VERSION ""

NS_ :

BS_:

BU_:

BO_ 2183149062 HeadLight_3606: 8 Vector__XXX
 SG_ HeadLightOn : 15|8@0+ (1,0) [0|0] "" Vector__XXX
 SG_ BusAwake : 7|8@0+ (1,0) [0|0] "" Vector__XXX

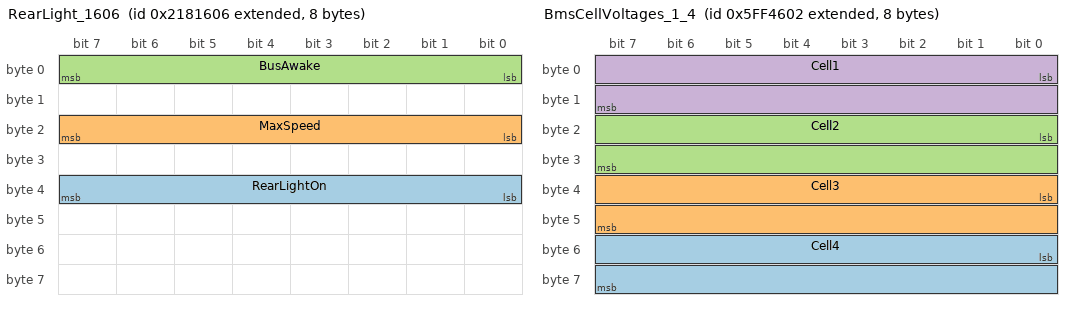
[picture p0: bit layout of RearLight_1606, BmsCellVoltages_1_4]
BO_ 2182616582 RearLight_1606: 8 Vector__XXX
 SG_ RearLightOn : 39|8@0+ (1,0) [0|0] "" Vector__XXX
 SG_ MaxSpeed : 23|8@0+ (1,0) [0|0] "km/h" Vector__XXX
 SG_ BusAwake : 7|8@0+ (1,0) [0|0] "" Vector__XXX

BO_ 2478269440 Lock_6400: 1 Vector__XXX
 SG_ Unlocked : 7|8@0+ (1,0) [0|0] "" Vector__XXX

BO_ 2214532608 SpeedLimit_1600: 8 Vector__XXX
 SG_ MaxSpeed : 63|8@0+ (1,0) [0|0] "km/h" Vector__XXX

BO_ 2248099330 BmsCellVoltages_1_4: 8 Vector__XXX
 SG_ Cell4 : 48|16@1+ (1,0) [0|0] "mV" Vector__XXX
 SG_ Cell3 : 32|16@1+ (1,0) [0|0] "mV" Vector__XXX
 SG_ Cell2 : 16|16@1+ (1,0) [0|0] "mV" Vector__XXX
 SG_ Cell1 : 0|16@1+ (1,0) [0|0] "mV" Vector__XXX

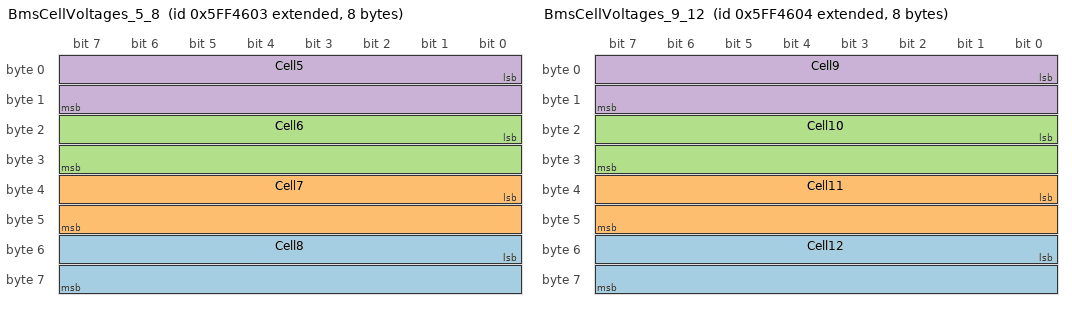
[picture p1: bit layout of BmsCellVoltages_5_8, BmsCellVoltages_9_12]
BO_ 2248099331 BmsCellVoltages_5_8: 8 Vector__XXX
 SG_ Cell8 : 48|16@1+ (1,0) [0|0] "mV" Vector__XXX
 SG_ Cell7 : 32|16@1+ (1,0) [0|0] "mV" Vector__XXX
 SG_ Cell6 : 16|16@1+ (1,0) [0|0] "mV" Vector__XXX
 SG_ Cell5 : 0|16@1+ (1,0) [0|0] "mV" Vector__XXX

BO_ 2248099332 BmsCellVoltages_9_12: 8 Vector__XXX
 SG_ Cell12 : 48|16@1+ (1,0) [0|0] "mV" Vector__XXX
 SG_ Cell11 : 32|16@1+ (1,0) [0|0] "mV" Vector__XXX
 SG_ Cell10 : 16|16@1+ (1,0) [0|0] "mV" Vector__XXX
 SG_ Cell9 : 0|16@1+ (1,0) [0|0] "mV" Vector__XXX

BO_ 2248099333 BmsCellVoltage_13: 8 Vector__XXX
 SG_ Cell13 : 0|16@1+ (1,0) [0|0] "mV" Vector__XXX

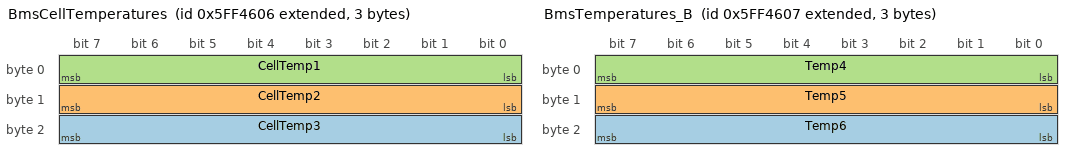
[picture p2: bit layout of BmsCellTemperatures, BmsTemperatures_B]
BO_ 2248099334 BmsCellTemperatures: 3 Vector__XXX
 SG_ CellTemp3 : 23|8@0+ (1,0) [0|0] "degC" Vector__XXX
 SG_ CellTemp2 : 15|8@0+ (1,0) [0|0] "degC" Vector__XXX
 SG_ CellTemp1 : 7|8@0+ (1,0) [0|0] "degC" Vector__XXX

BO_ 2248099335 BmsTemperatures_B: 3 Vector__XXX
 SG_ Temp6 : 23|8@0+ (1,0) [0|0] "degC" Vector__XXX
 SG_ Temp5 : 15|8@0+ (1,0) [0|0] "degC" Vector__XXX
 SG_ Temp4 : 7|8@0+ (1,0) [0|0] "degC" Vector__XXX

BO_ 2248099344 BmsPackVoltageCurrent: 8 Vector__XXX
 SG_ PackCurrent : 39|32@0- (1,0) [0|0] "mA" Vector__XXX
 SG_ PackVoltage : 7|32@0+ (1,0) [0|0] "mV" Vector__XXX

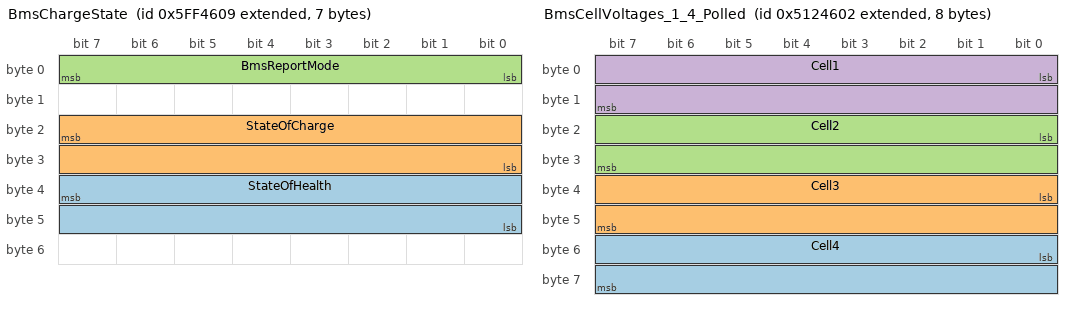
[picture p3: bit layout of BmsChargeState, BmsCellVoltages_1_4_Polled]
BO_ 2248099337 BmsChargeState: 7 Vector__XXX
 SG_ StateOfHealth : 39|16@0+ (0.1,0) [0|0] "%" Vector__XXX
 SG_ StateOfCharge : 23|16@0+ (0.1,0) [0|0] "%" Vector__XXX
 SG_ BmsReportMode : 7|8@0+ (1,0) [0|0] "" Vector__XXX

BO_ 2232567305 BmsChargeStatePolled: 7 Vector__XXX
 SG_ StateOfHealth : 39|16@0+ (0.1,0) [0|0] "%" Vector__XXX
 SG_ StateOfCharge : 23|16@0+ (0.1,0) [0|0] "%" Vector__XXX

BO_ 2232567297 BmsStatusFlagsPolled: 6 Vector__XXX

BO_ 2232567298 BmsCellVoltages_1_4_Polled: 8 Vector__XXX
 SG_ Cell4 : 48|16@1+ (1,0) [0|0] "mV" Vector__XXX
 SG_ Cell3 : 32|16@1+ (1,0) [0|0] "mV" Vector__XXX
 SG_ Cell2 : 16|16@1+ (1,0) [0|0] "mV" Vector__XXX
 SG_ Cell1 : 0|16@1+ (1,0) [0|0] "mV" Vector__XXX

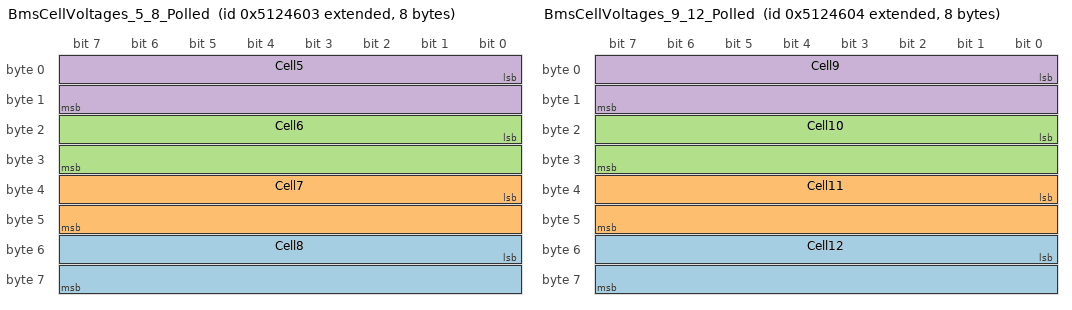
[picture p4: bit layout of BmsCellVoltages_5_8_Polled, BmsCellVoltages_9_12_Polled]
BO_ 2232567299 BmsCellVoltages_5_8_Polled: 8 Vector__XXX
 SG_ Cell8 : 48|16@1+ (1,0) [0|0] "mV" Vector__XXX
 SG_ Cell7 : 32|16@1+ (1,0) [0|0] "mV" Vector__XXX
 SG_ Cell6 : 16|16@1+ (1,0) [0|0] "mV" Vector__XXX
 SG_ Cell5 : 0|16@1+ (1,0) [0|0] "mV" Vector__XXX

BO_ 2232567300 BmsCellVoltages_9_12_Polled: 8 Vector__XXX
 SG_ Cell12 : 48|16@1+ (1,0) [0|0] "mV" Vector__XXX
 SG_ Cell11 : 32|16@1+ (1,0) [0|0] "mV" Vector__XXX
 SG_ Cell10 : 16|16@1+ (1,0) [0|0] "mV" Vector__XXX
 SG_ Cell9 : 0|16@1+ (1,0) [0|0] "mV" Vector__XXX

BO_ 2232567301 BmsCellVoltage_13_Polled: 8 Vector__XXX
 SG_ Cell13 : 0|16@1+ (1,0) [0|0] "mV" Vector__XXX

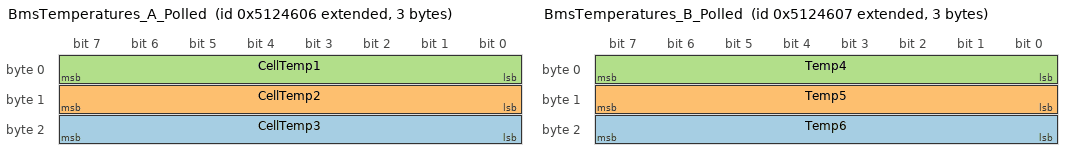
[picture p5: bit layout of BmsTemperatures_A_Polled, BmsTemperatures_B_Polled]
BO_ 2232567302 BmsTemperatures_A_Polled: 3 Vector__XXX
 SG_ CellTemp3 : 23|8@0+ (1,0) [0|0] "degC" Vector__XXX
 SG_ CellTemp2 : 15|8@0+ (1,0) [0|0] "degC" Vector__XXX
 SG_ CellTemp1 : 7|8@0+ (1,0) [0|0] "degC" Vector__XXX

BO_ 2232567303 BmsTemperatures_B_Polled: 3 Vector__XXX
 SG_ Temp6 : 23|8@0+ (1,0) [0|0] "degC" Vector__XXX
 SG_ Temp5 : 15|8@0+ (1,0) [0|0] "degC" Vector__XXX
 SG_ Temp4 : 7|8@0+ (1,0) [0|0] "degC" Vector__XXX

BO_ 2232567312 BmsPackVoltageCurrentPolled: 8 Vector__XXX
 SG_ PackCurrent : 39|32@0- (1,0) [0|0] "mA" Vector__XXX
 SG_ PackVoltage : 7|32@0+ (1,0) [0|0] "mV" Vector__XXX

BO_ 2298049792 Node75HardwareVersion: 8 Vector__XXX
 SG_ HardwareVersion : 7|32@0+ (1,0) [0|0] "" Vector__XXX

BO_ 2298049793 Node75FirmwareVersion: 8 Vector__XXX
 SG_ FirmwareVersion : 7|32@0+ (1,0) [0|0] "" Vector__XXX

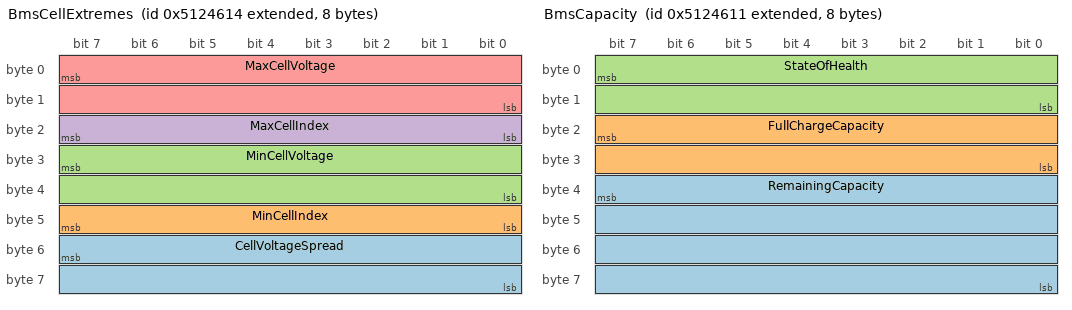
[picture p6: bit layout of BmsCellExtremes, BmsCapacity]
BO_ 2232567316 BmsCellExtremes: 8 Vector__XXX
 SG_ CellVoltageSpread : 55|16@0+ (1,0) [0|0] "mV" Vector__XXX
 SG_ MinCellIndex : 47|8@0+ (1,0) [0|0] "" Vector__XXX
 SG_ MinCellVoltage : 31|16@0+ (1,0) [0|0] "mV" Vector__XXX
 SG_ MaxCellIndex : 23|8@0+ (1,0) [0|0] "" Vector__XXX
 SG_ MaxCellVoltage : 7|16@0+ (1,0) [0|0] "mV" Vector__XXX

BO_ 2232567313 BmsCapacity: 8 Vector__XXX
 SG_ RemainingCapacity : 39|32@0+ (1,0) [0|0] "mAh" Vector__XXX
 SG_ FullChargeCapacity : 23|16@0+ (1,0) [0|0] "mAh" Vector__XXX
 SG_ StateOfHealth : 7|16@0+ (1,0) [0|0] "%" Vector__XXX

BO_ 2248099328 BmsConfig: 6 Vector__XXX
 SG_ CellCount : 7|8@0+ (1,0) [0|0] "" Vector__XXX

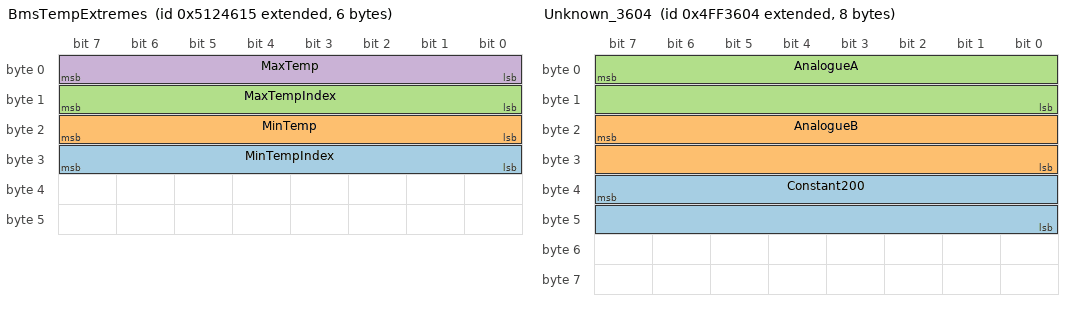
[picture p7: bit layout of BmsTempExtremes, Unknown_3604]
BO_ 2232567317 BmsTempExtremes: 6 Vector__XXX
 SG_ MinTempIndex : 31|8@0+ (1,0) [0|0] "" Vector__XXX
 SG_ MinTemp : 23|8@0+ (1,0) [0|0] "degC" Vector__XXX
 SG_ MaxTempIndex : 15|8@0+ (1,0) [0|0] "" Vector__XXX
 SG_ MaxTemp : 7|8@0+ (1,0) [0|0] "degC" Vector__XXX

BO_ 2214532352 Node15HardwareVersion: 8 Vector__XXX
 SG_ HardwareVersion : 7|32@0+ (1,0) [0|0] "" Vector__XXX

BO_ 2214532353 Node15FirmwareVersion: 8 Vector__XXX
 SG_ FirmwareVersion : 7|32@0+ (1,0) [0|0] "" Vector__XXX

BO_ 2230924544 Node35HardwareVersion: 8 Vector__XXX
 SG_ HardwareVersion : 7|32@0+ (1,0) [0|0] "" Vector__XXX

BO_ 2230924545 Node35FirmwareVersion: 8 Vector__XXX
 SG_ FirmwareVersion : 7|32@0+ (1,0) [0|0] "" Vector__XXX

BO_ 2232567040 Node45HardwareVersion: 2 Vector__XXX
 SG_ HardwareVersion : 7|16@0+ (1,0) [0|0] "" Vector__XXX

BO_ 2232567041 Node45FirmwareVersion: 2 Vector__XXX
 SG_ FirmwareVersion : 7|16@0+ (1,0) [0|0] "" Vector__XXX

BO_ 2232567042 BmsModelString: 8 Vector__XXX

BO_ 2232567043 BmsManufactureInfo: 8 Vector__XXX

BO_ 2231317504 Uptime_3400: 8 Vector__XXX
 SG_ Uptime : 23|16@0+ (10,0) [0|0] "s" Vector__XXX

BO_ 2197300224 AwakeTime_2400: 8 Vector__XXX
 SG_ AwakeTime : 0|16@1+ (10,0) [0|0] "s" Vector__XXX

BO_ 2214532096 AwakeTime_1400: 8 Vector__XXX
 SG_ AwakeTime : 7|32@0+ (10,0) [0|0] "s" Vector__XXX

BO_ 2248098816 BmsSequence_4400: 4 Vector__XXX
 SG_ Sequence : 7|32@0+ (1,0) [0|0] "" Vector__XXX

BO_ 2197759490 AuthNonce_2602: 8 Vector__XXX

BO_ 2185700866 AuthChallengeMeUnlock: 8 Vector__XXX

BO_ 2231318020 Unknown_3604: 8 Vector__XXX
 SG_ Constant200 : 39|16@0+ (1,0) [0|0] "" Vector__XXX
 SG_ AnalogueB : 23|16@0+ (1,0) [0|0] "" Vector__XXX
 SG_ AnalogueA : 7|16@0+ (1,0) [0|0] "" Vector__XXX

BO_ 2214532611 Speed_1603: 8 Vector__XXX
 SG_ VoltageLike : 23|16@0+ (1,0) [0|0] "mV" Vector__XXX
 SG_ Speed : 7|16@0+ (0.1,0) [0|0] "km/h" Vector__XXX

BO_ 2214531072 Heartbeat_1000: 8 Vector__XXX
 SG_ SystemReady : 3|1@0+ (1,0) [0|0] "" Vector__XXX

BO_ 2683875368 LockTransition_B028: 8 Vector__XXX

BO_ 2214532610 Distance_1602: 8 Vector__XXX
 SG_ TripDistance : 39|16@0+ (1,0) [0|0] "m" Vector__XXX
 SG_ Odometer : 7|24@0+ (10,0) [0|0] "m" Vector__XXX

BO_ 2214532612 Unknown_1604: 8 Vector__XXX

CM_ BO_ 2183149062 "[confirmed] The headlight. Identified by remote command: the console logged HLON at
1788785214.368 and HLOFF at 1788785234.208, and this message changed 0.77 s and
0.33 s later respectively. Nothing else on the bus changed in either window
except the uptime counter ticking.";
CM_ SG_ 2183149062 HeadLightOn "[confirmed] Byte 1. Goes to 1 within 0.77 s of the HLON command and to 0 within 0.33 s of
HLOFF, then to 1 again 2.0 s after UNLOCK and to 0 1.3 s after LOCK -- so
unlocking the bike switches the headlight on, which is why the periodic GTFRI
report still showed head_light_status=1 after HLOFF. Cross-checks against
<ECU Info> field 5 (Head Light Status) in the same session.";
CM_ SG_ 2183149062 BusAwake "[confirmed] Byte 0. 1 = the bike is awake, 2 = asleep. Bytes 3 and 5 carry the same fact
inverted: b0=1 goes with b3=b5=1, and b0=2 with b3=b5=0, in every one of the
311 frames of the three 7 September sessions. Bytes 0, 3 and 5 are one signal.

CORRECTION. This byte was previously recorded as \"HeadLightSource\", on the
reading that 0x02 meant the change came from an explicit HLON/HLOFF command
and 0x01 from the unlock sequence. That was wrong, and the 4 September corpus
disproves it on its own: that recording contains no UNLOCK at all, yet byte 0
is 2 in all 103 frames while byte 1 still toggles the headlight on and off.
Byte 0 says nothing about who asked.

What it does track is the lock. Against the HubLock's own state on 13B76400 it
agrees in 60/61, 116/120 and 115/120 frames across the three sessions, the
disagreements all being frames inside a transition. It is 2 throughout the
4 September corpus, which is a bike that was never unlocked.

WHY IT MATTERS BEYOND THIS MESSAGE. Unlocking the bike wakes the bus: 5
identifiers become 94. This byte is that state, published at a lamp's address,
which is why the headlight appeared to switch on by itself after UNLOCK.

CORRECTION -- this byte and 02181606 byte 0 are NOT the same fact. Two
recordings show the bus woken without an UNLOCK: the reboot session, where
each of three IoT REBOOT commands woke ~65 identifiers for about 5 s, and the
190 s after the last pack restore in the battery-removal session. In both,
02181606 byte 0 reads 1 (its full awake payload) while this byte stays 2 in
every frame, and the console reports the bike locked. So 02181606 byte 0 says
component 1 (AA=16) is awake; this byte says component 3 (AA=36) is awake,
which so far has happened only on UNLOCK. 04FF3604 never joins those
IoT-triggered wakes either, which puts it with this byte at component 3.";
CM_ BO_ 2182616582 "[confirmed] The rear light. Same method as the headlight: RLONEN at 1788785392.364 and
RLOFF at 1788785412.125, with this message changing 0.76 s and 0.40 s later,
and nothing else changing in either window.";
CM_ SG_ 2182616582 RearLightOn "[confirmed] Byte 4. Goes to 1 within 0.76 s of RLONEN and to 0 within 0.40 s of RLOFF, and
also tracks UNLOCK (0.28 s) and LOCK (0.52 s). Cross-checks against <ECU Info>
field 6 (Rear Light Status).";
CM_ SG_ 2182616582 MaxSpeed "[confirmed] CORRECTION -- this signal was called RearLightAwakeLevel and read as a
brightness percentage. It is not a light signal at all. It is the configured
maximum assisted speed, the same value 03FF1600 byte 7 carries, mirrored at
the rear light's address.

CONFIRMED -- by the same six commands, in the same session, as 03FF1600. Byte 2
followed each one:

    UNLOCK       0100120001030200   byte 2 = 18
    GTECC:19     0100130001030200   byte 2 = 19
    GTECC:25     0100190001030200   byte 2 = 25
    GTECC:15     01000F0001030200   byte 2 = 15
    GTECC:10     01000A0001030200   byte 2 = 10
    GTECC:5      0100050001030200   byte 2 =  5
    GTECC:25     0100190001030200   byte 2 = 25
    LOCK         0000000000030200   byte 2 =  0

A search over every identifier and every byte position for the commanded
sequence [18, 19, 25, 15, 10, 5, 25] returned exactly two hits: this byte and
03FF1600 byte 7. Nothing else on the bus carries the value.

WHY THE OLD READING WAS REASONABLE, AND WHAT ACTUALLY DISPROVED IT. The
previous note observed correctly that byte 2 held 25 while awake and 0 while
asleep, and reasoned that 25 in a byte with only two values looked like a
percentage. Both halves were sound. The trap was that 25 km/h is the EU
pedelec limit, so the factory value of a configuration byte is indistinguishable
from a constant until somebody reconfigures it -- and the 0 when asleep is the
ECU not publishing, not a measured zero.

The test the old note proposed -- command RLONEN on an unlocked bike and see
where byte 2 lands -- would NOT have caught this. Byte 2 does not respond to
the lamp at any lock state. What caught it was changing the thing itself.

The 0 while asleep is now read the same way as every other zeroed ECU field:
absence of data, not a measurement. See nodes.md.

WHAT THIS DOES NOT DISTURB. Byte 0 (BusAwake) and byte 4 (RearLightOn) are
unaffected and stay confirmed. The observation that separated them from byte 2
in the first place -- with the bike locked, RLONEN turns byte 4 on while byte 2
stays 0 -- still holds and now has a plainer explanation: byte 4 is the lamp
and byte 2 was never about the lamp.";
CM_ SG_ 2182616582 BusAwake "[confirmed] Byte 0. 1 = the bike is awake, 0 = asleep. The same fact that byte 0 of
02203606 carries, in the same sense as the lock rather than inverted.

Agrees with the HubLock's own state on 13B76400 in 99/100 and 115/120 frames,
and is 0 throughout the 4 September corpus, which is a bike that was never
unlocked. It is 0 through the RLONEN window of the 7 September session too,
while byte 4 turns the lamp on -- which is what separates the two signals.

CORRECTION -- it is \"component 1 awake\", not \"unlocked\". In the reboot
session each IoT REBOOT woke the bus for about 5 s with the bike locked, and
this byte read 1 in 18 of 30 frames; the same happened for 190 s after the
last pack restore in the battery-removal session (32 of 51 frames before the
UNLOCK). 02203606 byte 0 stayed at 2 (asleep) in every one of those frames, and
+RESP:GTFRI reported ECU Lock State = 1 throughout. The agreement with the
lock recorded above is real but only because every wake in those sessions was
an unlock. See nodes.md, \"An IoT reboot wakes the bus\".

CAUTION on byte 4 in that state: the same frames carry byte 4 = 1 and byte 2 =
25 -- the whole payload is the awake payload, 0100190001030200 -- while GTFRI
reports Rear Light Status = 0. Whether the lamp was physically lit during those
wakes was not observed. RearLightOn stays confirmed on the commanded evidence
above; this is a note that its value during an IoT-triggered wake is untested.";
CM_ BO_ 2478269440 "[confirmed] The lock (immobiliser) reporting its state. A single-byte message, and the only
one on the bus with priority 0x13.

NOT PERIODIC. This carried cycle_time_ms = 280 and that was misleading: 280 ms
is the spacing inside a burst, not a cycle. Over the two sessions where the
HubLock was fitted it sent about 20 frames (5.3 s) after each UNLOCK and three
bursts of three frames, 2.8 s apart, after each LOCK, and nothing in between --
29 frames in a 7073 s session. It is absent from the 4 September corpus, which
contains no lock event. So an inventory of a sleeping bus does not show it, and
its absence from a short recording says nothing about whether the HubLock is
fitted; only a lock event does.

Identified across two independent sessions by driving UNLOCK and LOCK remotely
and watching which byte tracked the resulting state. Method: build the lock
state timeline from the +RESP:GTMLS reports, then look for bytes whose value
sets are disjoint between locked and unlocked intervals. Exactly one byte
qualified across 2 locked and 2 unlocked intervals.

CONFIRMED BY DISCONNECTION: a third session was recorded with the HubLock
disabled. This identifier went from 139 frames to zero, and it was the ONLY
identifier to disappear -- 95 identifiers became 94, with none appearing in its
place. Both lamps still toggled normally in that session, so the bus was
healthy and the remote commands were still being processed. The component that
sends this is therefore the HubLock, and AA=0x64 is its address.

NOT the battery lock. <ECU Info> field 13 (Battery-Lock State) stayed 0 through
all three sessions while this byte flipped.";
CM_ SG_ 2478269440 Unlocked "[confirmed] Byte 0. 1 = unlocked, 0 = locked -- note this is the inverse of GTFRI's
ECU Lock State field, so it reads as an \"unlocked\" flag. Named for what the
raw value means rather than inverting it here.

Six transitions across two sessions, every one following its command:
  UNLOCK -> 1 after 2.12 s, 2.55 s, 2.17 s
  LOCK   -> 0 after 0.32 s, 0.46 s, 0.58 s

CORRECTION -- what the asymmetry measures. This was recorded as evidence of a
motorised latch, on the grounds that unlocking takes about four times as long
as locking. That reading does not survive: the whole bus shows the same
asymmetry. 04FF3604, the 30 ms message, starts 2.1-2.6 s after each UNLOCK and
stops 0.3-0.8 s after each LOCK, in all four unlock and three lock events
across the three 7 September sessions. So the 2.1 s is the wake sequence
bringing 89 identifiers up, and this byte is simply reported at the end of it.
The asymmetry still argues against a command echo, but it says nothing about
the latch.

Repeated UNLOCK commands on an already-unlocked bike produce no transition, so
this byte reports actual state and not command receipt. That is why session 2's
six UNLOCK commands yielded only two unlock transitions.

DO NOT use GTFRI's ECU Lock State as a substitute for this signal. With the
HubLock disabled and no 13B76400 on the bus at all, that field still reported
lock_state flipping 0 and 1, so it tracks what the IoT module believes rather
than what the lock did.";
CM_ BO_ 2214532608 "[confirmed] The configured maximum assisted speed. Published at 1 Hz while the bike is
awake and absent entirely while it is locked -- in the unlock/lock session the
first frame arrives 0.8 s after each UNLOCK and the last one lands before each
LOCK.

Only byte 7 was ever seen to move. The rest held 14 2B 00 01 04 00 13 across
every session on record, through six speed changes, a lock cycle and a session
boundary.";
CM_ SG_ 2214532608 MaxSpeed "[confirmed] CONFIRMED -- tied to a commanded action, six times in one session. The
set-speed-while-unlocked session sent six AT+GTECC commands to an awake bike
and byte 7 followed every one of them, on the CAN log's own clock:

    command      byte 7    latency
    (at open)        18    carried in from the previous session
    GTECC:19         19    1.39 s
    GTECC:25         25    1.26 s
    GTECC:15         15    0.89 s
    GTECC:10         10    1.21 s
    GTECC:5           5    0.81 s
    GTECC:25         25    1.29 s

Six commanded values, six matches, no misses and no intermediate values. The
message runs at 1 Hz, so a latency of 0.8-1.4 s is one period plus the command
round trip -- there is no room in that for the byte to have reached the value
any other way.

CONFIRMED -- the scale, as 1:1 km/h with no offset, over 5 to 25. Six distinct
commanded values is enough to fix a linear scale outright rather than infer it.

CONFIRMED -- that it persists. The session opened at 18, which is where the
previous session's last GTECC left it, across an intervening lock and a gap in
recording. So this is stored configuration and not a transient.

WHY 25 LOOKED LIKE SOMETHING ELSE FOR SO LONG. Every session before the first
GTECC read 25, because 25 km/h is the EU pedelec limit and nobody had changed
it. A configuration byte nobody has reconfigured is indistinguishable from a
constant. See the correction on 02181606 MaxSpeed, which is this same value
mirrored at the rear light's address and was read as a brightness percentage
for exactly this reason.

UNKNOWN -- byte 6, which holds 19 and did not move through any of the six
commands. A second limit of some kind is the obvious guess and there is no
evidence for it. Note that 19 is also a value GTECC was given, which makes it
easy to misread a coincidence as a match; byte 6 held 19 both before and after
that command.

TO DISPROVE. Command a value outside the 5-25 range tested here -- 0, or 40 --
and see whether byte 7 follows, clamps, or the command is refused. A clamp
would say the ECU bounds what it accepts, which the range tested cannot show.";
CM_ BO_ 2248099330 "[confirmed] BMS cell voltages, cells 1-4. Confirmed without guesswork: the +RESP:GTBMI
report relays this frame's payload verbatim -- the identical byte string
1410191019101910 appears both in the CAN payload and in the report -- and
GTBMI states a cell count of 13, which is exactly what 05FF4602 through
05FF4605 supply (4+4+4+1). The 13 cells sum to 53.622 V against the 53.696 V
that GTFRI reported for the pack at the same moment, a 0.14 % difference.";
CM_ SG_ 2248099330 Cell4 "[confirmed] Little-endian uint16 in mV.";
CM_ SG_ 2248099330 Cell3 "[confirmed] Little-endian uint16 in mV.";
CM_ SG_ 2248099330 Cell2 "[confirmed] Little-endian uint16 in mV.";
CM_ SG_ 2248099330 Cell1 "[confirmed] Little-endian uint16 in mV: bytes 14 10 read as 0x1014 = 4116 mV.";
CM_ BO_ 2248099331 "[confirmed] BMS cell voltages, cells 5-8. Relayed verbatim in +RESP:GTBMI.";
CM_ SG_ 2248099331 Cell8 "[confirmed] Little-endian uint16 in mV.";
CM_ SG_ 2248099331 Cell7 "[confirmed] Little-endian uint16 in mV.";
CM_ SG_ 2248099331 Cell6 "[confirmed] Little-endian uint16 in mV.";
CM_ SG_ 2248099331 Cell5 "[confirmed] Little-endian uint16 in mV.";
CM_ BO_ 2248099332 "[confirmed] BMS cell voltages, cells 9-12. Relayed verbatim in +RESP:GTBMI.";
CM_ SG_ 2248099332 Cell12 "[confirmed] Little-endian uint16 in mV.";
CM_ SG_ 2248099332 Cell11 "[confirmed] Little-endian uint16 in mV.";
CM_ SG_ 2248099332 Cell10 "[confirmed] Little-endian uint16 in mV.";
CM_ SG_ 2248099332 Cell9 "[confirmed] Little-endian uint16 in mV.";
CM_ BO_ 2248099333 "[confirmed] BMS cell voltage, cell 13, then padding. This pack has 13 cells, so the last
frame of the series carries one value and six zero bytes -- which is how the
cell count was established.";
CM_ SG_ 2248099333 Cell13 "[confirmed] Little-endian uint16 in mV. Bytes 2-7 are always zero: only 13 cells.";
CM_ BO_ 2248099334 "[confirmed] BMS cell temperatures, three sensors. Was BmsTemperatures_A. Payload 1C1C1C
reads as 28, 28, 28 degC, and the same byte string is relayed in +RESP:GTBMI
immediately after the cell voltage frames. That these three are the CELL
sensors, as opposed to the three in 05FF4607, rests on 05124615 -- see the
correction below.

CORRECTION -- WITHDRAWN: the earlier note here said no byte of this frame or
05FF4607 could be the cell maximum, because <ECU Info>'s Cell Temperature Max
changed within a session while all six bytes held still. Both halves of that
argument fail. The bytes do move (05FF4607 byte 1 toggles 27/28 within
session 2, byte 0 toggles 28/29 within session 1). And <ECU Info>'s
temperatures are a CACHED COPY, not a live reading: in sessions 1, 2 and the
battery-removal session the console's cell max/min changed only in the first
report after a 05124615 poll reply, and to exactly that reply's values
(28/28 after 1C011C01; 29/28 after 1D011C03; 30/29 after 1E011D03). Comparing
a cached copy in time against a live frame proves nothing either way.

WHAT THE CORPUS DOES SHOW: these three bytes are the cell temperature sensors.
05124615 reports a maximum and a minimum each with a 1-based sensor index, and
in all 12 frames on record across five sessions the indexed byte of THIS frame
carries exactly the reported value -- 29 29 28 with max 29 @ 1 and min 28 @ 3;
30 30 29 with 30 @ 1 and 29 @ 3; 30 30 30 with 30 @ 1 and 30 @ 1. The indices
never point into 05FF4607, whose bytes 1 and 2 sit below the reported cell
minimum. That is the same internal-consistency test that confirmed 05124614
against the cell voltages, so the cell-sensor reading is confirmed; which
physical position each of the three sensors occupies in the pack is not.

The whole corpus spans 27 to 30 degC. To go further, warm one part of the
pack -- a charge cycle heats the MOS, a discharge heats the cells -- and see
which bytes move together.";
CM_ SG_ 2248099334 CellTemp3 "[confirmed] Was Temp3. Cell sensor 3: 05124615 names it (index 3) as the cell minimum
whenever the minimum differs from the maximum -- 28 in sessions 2 and 3, 29 in
the battery-removal session -- and the value matches every time.";
CM_ SG_ 2248099334 CellTemp2 "[probable] Was Temp2. Cell sensor 2 by position between the two that 05124615 indexes.
Never itself named as max or min in the corpus, so probable rather than
confirmed.";
CM_ SG_ 2248099334 CellTemp1 "[confirmed] Was Temp1. Cell sensor 1: 05124615 names it (index 1) as the sensor holding
the cell maximum in all 12 polled frames, and the value matches every time
(28, 29, 30 across sessions). Confirmed by internal consistency, as 05124614.
Scale 1 degC with no offset is inferred from the same match; an offset would
have to be shared by both frames.";
CM_ BO_ 2248099335 "[probable] More BMS temperatures: 1D1B1C reads as 29, 27, 28 degC, and is likewise
relayed verbatim in +RESP:GTBMI. The spread across the two frames is 27-29 degC
on a stationary bike at room temperature, which is what makes the reading
plausible.

These are the NON-cell sensors. 05124615's max/min indices point into
05FF4606 in all 12 frames and never here, and bytes 1 and 2 of this frame sit
at or below the reported cell minimum. Byte 0 equals <ECU Info>'s MOS
temperature in every session where that field had been freshly refreshed by a
poll (sessions 2, 3, 4 and 9: 29, 29, 30, 30). See Temp4.";
CM_ SG_ 2248099335 Temp6 "[probable] 0x1C = 28 degC. Sensor identity unknown.";
CM_ SG_ 2248099335 Temp5 "[probable] 0x1B = 27 degC, and the one temperature byte whose identity can be settled by
elimination: it is NOT a cell sensor.

In every @Track report of every session <ECU Info> gives Cell Temperature Min
as 28 degC. This byte reads 27. A pack cannot have a cell colder than its
reported cell minimum, so whatever this sensor measures, the BMS does not
count it as a cell. It is not the MOS or \"other\" temperature either -- both
are reported as 28 or 29 and this byte matched neither in any of the 21
comparable reports.

UPDATE. The byte does move: 27 or 28 within session 2, 28 in session 3, 29 in
the battery-removal, unlock/lock and set-speed sessions. It stays at or below
the cell minimum that 05124615 reports at the time (28, 28, 29, 30, 30), so
the \"not a cell\" argument survives the wider corpus. The MOS comparison above
was made against a cached console value; the fresh comparison is that byte 0
of this frame, not this byte, tracks mos_temp_c.

Ambient, board or inlet temperature are what is left. Untested.";
CM_ SG_ 2248099335 Temp4 "[probable] 0x1D = 29 degC. Probably the MOS temperature: matches <ECU Info> mos_temp_c in
sessions 2, 3, 4 and 9 (29, 29, 30, 30). Session 1 disagrees (byte 29, console
28), but the console's copy there predates the session's only poll, so it is
stale -- see the CORRECTION on 05FF4606 for why the console's temperatures
cannot be read as live. Not confirmed because a constant matching a constant
over 29-30 degC is weak; a charge cycle would move the MOS and settle it.";
CM_ BO_ 2248099344 "[confirmed] The BMS reporting the pack terminals: voltage in bytes 0-3, current in bytes
4-7, both big-endian 32-bit, both at 273 ms. This was the \"273 ms, bytes 3 and
7 varying, at the BMS address, not part of the GTBMI relay\" entry in nodes.md.

Two independent confirmations, which is why this is the best-established
message on the bus after the cell voltages themselves:

1. The current bytes appear VERBATIM in the serial console. The last four
   bytes of <Battery Status> in +RESP:GTFRI are the pack current, and 27 of
   the 29 reports across the three 7 September sessions carry byte-for-byte
   the same value as the nearest frame of this message -- FFFFFFA9, FFFFFF9E,
   FFFFFFCA and so on, matched to within 0.1 s. The two that differ are
   adjacent samples of a value that changes every 273 ms.

2. The voltage agrees with a signal confirmed by a different route. Summing
   the 13 cells of 05FF4602-05FF4605 gives the same number to within 2 mV on
   96.9 %, 97.1 % and 98.7 % of the three sessions' frames (693 in total),
   worst case 6 mV. The two are measured and transmitted separately, so they
   are not the same reading twice, and the residual is the sampling offset
   between a 273 ms message and a 1044 ms one.

Note the voltage here reads 73-93 mV BELOW what +RESP:GTFRI gives as
<Main Power Voltage> (median 84 mV over 22 comparable reports). That is expected: GTFRI's figure is the tracker
measuring its own supply rail, which is why GTFRI still reports a pack voltage
on a locked bike with the BMS asleep and this message absent. Do not treat the
two as interchangeable.";
CM_ SG_ 2248099344 PackCurrent "[confirmed] Bytes 4-7, big-endian, SIGNED, mA. 0xFFFFFFA9 is -87 mA, not 4294967209.

The sign is not an inference. Every frame in all three sessions reads negative
(-32 to -104 mA), which is what a parked bike does: a small standing draw. The
same bytes reach the serial console unchanged, where the @Track parser already
treats the field as two's complement for the same reason.

Sign convention: negative is discharge. Nothing recorded so far charges the
pack, so the positive direction is untested. A charge cycle would settle it.";
CM_ SG_ 2248099344 PackVoltage "[confirmed] Bytes 0-3, big-endian, mV. 0x0000D176 = 53622 mV, which is exactly the sum of
the 13 cell voltages at the same moment. Bytes 0-1 have been zero in all 693
frames recorded, so the field could be 16 bits; 32 is written here because the
current field beside it demonstrably needs all four of its bytes for the sign.
Observed range 53562-53631 mV over three sessions.";
CM_ BO_ 2248099337 "[confirmed] State of charge and state of health. The BMS sends this unsolicited at 1044 ms
while the bike is awake; 05124609 is the identical payload returned when the
IoT module polls for it, which it does every 300 s even while the bike sleeps.
That poll is how the tracker can report a battery percentage on a locked bike,
and the pair 02294609 -> 05124609 is one of only five identifiers present on a
sleeping bus.";
CM_ SG_ 2248099337 StateOfHealth "[confirmed] Bytes 4-5, big-endian, 0.1 %. Matches <Battery Status> group 2, which the
@Track parser calls battery_health_pct:

  4 September   0x03E8 = 1000 -> 100.0 %   serial 100
  7 September   0x03CA =  970 ->  97.0 %   serial 97

Two values three days apart, both matching. A drop from 100 to 97 in three
days is not real degradation -- these estimates jump after a charge -- but the
agreement is what matters here.";
CM_ SG_ 2248099337 StateOfCharge "[confirmed] Bytes 2-3, big-endian, 0.1 %. Confirmed against <Scooter Battery Percentage>
in +RESP:GTFRI at four different values across the whole corpus:

  4 September   0x0370 =  880 ->  88.0 %   serial 88
  7 Sep, s1     0x03E8 = 1000 -> 100.0 %   serial 100
  7 Sep, s1     0x03DE =  990 ->  99.0 %   serial 99
  7 Sep, s2/s3  0x03D4 =  980 ->  98.0 %   serial 98

The step from 1000 to 990 is the strongest part. It happens on the bus at
t=918 s of the first session, and the serial's own reports go from 100 to 99
between t=914 s and t=1155 s -- so the CAN value changes inside the gap
between the two reports that bracket it. The bus leads the console, which is
the right way round for the bus being the source.

A 12-point range settles the scale. The serial reports whole percent, so the
0.1 resolution comes from this field being ten times the reported number in
every one of the four cases.";
CM_ SG_ 2248099337 BmsReportMode "[hypothesis] Byte 0 is 1 or 3. It is 1 on every 300 s poll reply while the bike is asleep
and 3 within a second or two of each UNLOCK, so it looks like the same
awake/asleep distinction that bytes 0 of 02203606 and 02181606 carry. Not
tested against anything else, and 1 and 3 is an odd pair for a boolean, so
this may be a mode with values not yet seen.";
CM_ BO_ 2232567305 "[confirmed] The reply to the IoT module's 02294609 poll, with the same layout as
05FF4609. Sent every 300 s, and one of the five identifiers that survive on a
sleeping bus -- so this frame, not the unsolicited one, is what the tracker
actually reports from most of the time.";
CM_ SG_ 2232567305 StateOfHealth "[confirmed] As 05FF4609.StateOfHealth.";
CM_ SG_ 2232567305 StateOfCharge "[confirmed] As 05FF4609.StateOfCharge; this is the frame the 88/99/100 % readings came from.";
CM_ BO_ 2232567297 "[hypothesis] Reply to 02294601. Payload 007300000000, identical to the unsolicited 05FF4601
and to the first block +RESP:GTBMI relays (0073000000000000, zero-extended to
eight). Constant in every frame ever recorded, so there is nothing to fit and
no signals are defined.

Byte 1 = 0x73 with everything else zero has the shape of a flag word -- GTBMI
places it where a protection/status field would sit -- but a constant is
consistent with any reading. What would test it: a pack fault, or a second
pack.";
CM_ BO_ 2232567298 "[confirmed] Reply to 02294602. Cells 1-4, as 05FF4602. Relayed verbatim in +RESP:GTBMI.";
CM_ SG_ 2232567298 Cell4 "[confirmed] As 05FF4602.Cell4.";
CM_ SG_ 2232567298 Cell3 "[confirmed] As 05FF4602.Cell3.";
CM_ SG_ 2232567298 Cell2 "[confirmed] As 05FF4602.Cell2.";
CM_ SG_ 2232567298 Cell1 "[confirmed] As 05FF4602.Cell1. 0B10 reads as 0x100B = 4107 mV.";
CM_ BO_ 2232567299 "[confirmed] Reply to 02294603. Cells 5-8, as 05FF4603. Relayed verbatim in +RESP:GTBMI.";
CM_ SG_ 2232567299 Cell8 "[confirmed] As 05FF4603.Cell8.";
CM_ SG_ 2232567299 Cell7 "[confirmed] As 05FF4603.Cell7.";
CM_ SG_ 2232567299 Cell6 "[confirmed] As 05FF4603.Cell6.";
CM_ SG_ 2232567299 Cell5 "[confirmed] As 05FF4603.Cell5.";
CM_ BO_ 2232567300 "[confirmed] Reply to 02294604. Cells 9-12, as 05FF4604. Relayed verbatim in +RESP:GTBMI.";
CM_ SG_ 2232567300 Cell12 "[confirmed] As 05FF4604.Cell12.";
CM_ SG_ 2232567300 Cell11 "[confirmed] As 05FF4604.Cell11.";
CM_ SG_ 2232567300 Cell10 "[confirmed] As 05FF4604.Cell10.";
CM_ SG_ 2232567300 Cell9 "[confirmed] As 05FF4604.Cell9.";
CM_ BO_ 2232567301 "[confirmed] Reply to 02294605. Cell 13, as 05FF4605. Bytes 2-7 are padding.";
CM_ SG_ 2232567301 Cell13 "[confirmed] As 05FF4605.Cell13.";
CM_ BO_ 2232567302 "[probable] Reply to 02294606. As 05FF4606: 1E1E1D reads as 30, 30, 29 degC -- the three
cell temperature sensors. See 05FF4606.";
CM_ SG_ 2232567302 CellTemp3 "[confirmed] As 05FF4606.CellTemp3.";
CM_ SG_ 2232567302 CellTemp2 "[probable] As 05FF4606.CellTemp2.";
CM_ SG_ 2232567302 CellTemp1 "[confirmed] As 05FF4606.CellTemp1; the polled frames carry the same bytes as the unsolicited frame beside them.";
CM_ BO_ 2232567303 "[probable] Reply to 02294607. As 05FF4607: 1E1D1D reads as 30, 29, 29 degC -- the
non-cell sensors, byte 0 probably the MOS. See 05FF4607.";
CM_ SG_ 2232567303 Temp6 "[probable] As 05FF4607.Temp6.";
CM_ SG_ 2232567303 Temp5 "[probable] As 05FF4607.Temp5.";
CM_ SG_ 2232567303 Temp4 "[probable] As 05FF4607.Temp4.";
CM_ BO_ 2232567312 "[confirmed] Reply to 02294610. The pack terminals, same layout as 05FF4610: voltage in
bytes 0-3, current in bytes 4-7, both big-endian 32-bit, the current signed.

Only four frames exist, all from the battery-removal session, and all four
decode against the serial console:

  rel  98.76  0000D0E3FFFFFFC4  53475 mV, -60 mA  |  GTFRI: 53.546 V, -60 mA
  rel 170.08  0000D0E3FFFFFFCA  53475 mV, -54 mA  |  GTFRI: 53.546 V, -54 mA
  rel 217.02  0000D0E3FFFFFFCA  53475 mV, -54 mA  |  GTFRI: 53.546 V, -60 mA
  rel 257.11  0000D0E1FFFFFFCF  53473 mV, -49 mA  |  GTFRI: 53.546 V, -54 mA

The current matches exactly in two of four; the other two are 3 s away from
their report, and the pack current moves every 273 ms. The voltage sits 71 mV
below GTFRI's <Main Power Voltage>, which is the same offset 05FF4610 shows
and for the same reason: GTFRI measures the tracker's own supply rail.";
CM_ SG_ 2232567312 PackCurrent "[confirmed] As 05FF4610.PackCurrent -- big-endian, SIGNED, mA. 0xFFFFFFC4 is -60 mA, and
+RESP:GTFRI reported exactly -60 mA 2.8 s earlier.";
CM_ SG_ 2232567312 PackVoltage "[confirmed] As 05FF4610.PackVoltage. 0x0000D0E3 = 53475 mV.";
CM_ BO_ 2298049792 "[probable] Reply to 02417500, in a request/reply family that had never been seen:
02 41 75 xx -> 08 F9 75 xx. Both appeared for the first time in the
7 September battery-removal session, 13 frames each, only during the sweep the
master runs when the pack is connected.

AA = 75 is a component the bus had never revealed. Under the nodes.md scheme
this is component 7, channel 5, and channel 5 is the identity channel at every
other address: BB = 00 hardware version, BB = 01 firmware version. The payload
shape agrees -- a single 32-bit value in bytes 0-3 with bytes 4-7 zero, exactly
like 03FF1500, 04F93500 and 05124500.

It is \"probable\" and not \"confirmed\" because <ECU Info> carries only three
version groups and all three are already accounted for by AA = 15, 35 and 45.
This component's version string reaches the serial console nowhere, so there
is no ground truth to check it against. What would settle it: a component
whose firmware version is known independently, or the spec PDF in reference/.";
CM_ SG_ 2298049792 HardwareVersion "[probable] Bytes 0-3 = 0x000000F4 = 244, constant across all 13 frames.";
CM_ BO_ 2298049793 "[probable] Reply to 02417501. See 08F97500 for the family and the caveat.";
CM_ SG_ 2298049793 FirmwareVersion "[probable] Bytes 0-3 = 0x00000015 = 21, constant across all 13 frames.";
CM_ BO_ 2232567316 "[confirmed] Highest and lowest cell, with which cell each one is, and the spread between
them. Returned on request (02294614) during the wake-up enumeration.

Confirmed by internal consistency against a signal established independently:
all 8 frames recorded across the three 7 September sessions agree exactly with
the maximum and minimum of the 13 cell voltages decoded from 05FF4602-4605 at
the same moment -- both values, BOTH INDICES, and the spread:

  10220B101400000E   4130 mV @ 11,  4116 mV @ 0,  spread 14
  101F0B101100000E   4127 mV @ 11,  4113 mV @ 0,  spread 14
  101D0B101000000D   4125 mV @ 11,  4112 mV @ 0,  spread 13

Eight frames, five fields each, no misses. Two indices matching by chance
across three sessions is not a plausible coincidence, and the values move
between sessions, so this is not a constant agreeing with a constant.

WORTH NOTING: the voltages here are BIG-endian, while the cell voltages in
05FF4602-4605 are little-endian. The same device uses both. Read big-endian,
0x1022 = 4130 mV, a credible cell; read little-endian it would be 8720 mV,
which is impossible, so the endianness is not a matter of taste here.

Cell indices are 0-based: cell 1 of the pack is index 0.";
CM_ SG_ 2232567316 CellVoltageSpread "[confirmed] Bytes 6-7 big-endian. Equal to MaxCellVoltage - MinCellVoltage in all 8
frames: 14, 14, 13 mV. Redundant with the two fields above, which is what
makes it a useful check that the frame has been read correctly.";
CM_ SG_ 2232567316 MinCellIndex "[confirmed] Byte 5. Always 0, and cell index 0 was in fact the lowest in all 8 frames.";
CM_ SG_ 2232567316 MinCellVoltage "[confirmed] Bytes 3-4 big-endian. 4116, 4114, 4113 and 4112 mV, each the true minimum.";
CM_ SG_ 2232567316 MaxCellIndex "[confirmed] Byte 2. Always 11 so far, and cell index 11 was in fact the highest in all 8 frames.";
CM_ SG_ 2232567316 MaxCellVoltage "[confirmed] Bytes 0-1 big-endian. 4130, 4127 and 4125 mV, each the true maximum of the 13 cells.";
CM_ BO_ 2232567313 "[confirmed] Pack capacity: how much charge the pack holds when full, and how much is left.
Returned on request (02294611) during the wake-up enumeration.

Confirmed by arithmetic against a signal confirmed by another route. Remaining
divided by full-charge, rounded to whole percent, is the state of charge that
05FF4609 reports and that the serial console repeats:

  13771 / 13964 = 98.62 %  ->  99   and SOC read 990
  13747 / 13964 = 98.45 %  ->  98   and SOC read 980
  13736 / 13964 = 98.37 %  ->  98   and SOC read 980

Remaining also falls monotonically across the three sessions, in the same
order and over the same hours as the pack voltage and the state of charge.

Bytes 0-1 hold 97, which is the state of health the serial console reports,
so the same number appears here and in 05FF4609 -- consistent, and a useful
cross-check on the frame.";
CM_ SG_ 2232567313 RemainingCapacity "[confirmed] Bytes 4-7 big-endian, mAh. 13771 -> 13747 -> 13736 across the three sessions,
falling monotonically. Divided by FullChargeCapacity it reproduces the
reported state of charge in every session.

Bytes 4-5 have always been zero. 32 bits is written here because the field
sits in the four bytes the frame has left; a pack this size will never fill
more than 16 of them.";
CM_ SG_ 2232567313 FullChargeCapacity "[confirmed] Bytes 2-3 big-endian, mAh. 0x368C = 13964, unchanged in all three sessions,
which is what a full-charge estimate should be over three hours.

Consistency: 13964 at 97 % health implies a design capacity near 14400 mAh,
which is a round number for a pack whose own model string is RP13S35A
(13 cells in series -- see 05124502). That is arithmetic, not evidence; the
confirmation is the SOC division in the message comment.";
CM_ SG_ 2232567313 StateOfHealth "[confirmed] Bytes 0-1 big-endian, whole percent. 0x0061 = 97, matching <Battery Status>
battery_health_pct in all three sessions. Note the units differ from
05FF4609.StateOfHealth, which carries the same quantity in 0.1 %.";
CM_ BO_ 2248099328 "[probable] Payload 0D0300900303, unchanged in every session. Byte 0 is 0x0D = 13, the
number of cells -- which +RESP:GTBMI states independently and which
05FF4602-05FF4605 supply exactly (4+4+4+1). The remaining five bytes are
0x03, 0x0090, 0x03, 0x03 and are not decoded; a pack configuration of some
kind, but nothing in the corpus varies them, so nothing can be fitted.";
CM_ SG_ 2248099328 CellCount "[probable] Byte 0 = 13. Agrees with the cell count +RESP:GTBMI reports and with the
number of cell voltage values on the bus. Still \"probable\" rather than
confirmed because a constant agreeing with a constant is weak: a pack with a
different cell count would settle it, and there is only one pack.";
CM_ BO_ 2232567317 "[confirmed] Highest and lowest temperature with sensor indices, by exact analogy with
05124614's treatment of the cell voltages. Returned on request (02294615).

  4 September onwards, s1     1C011C0100xx   28 @ 1, 28 @ 1
  7 September, s2 and s3      1D011C0301xx   29 @ 1, 28 @ 3

The two readings match <ECU Info>'s Cell Temperature Max and Min in the second
and third sessions (29 and 28) and in three of the five reports of the first.
The structural parallel with 05124614 -- value, index, value, index -- is what
makes the layout probable rather than a guess.

CONFIRMED by internal consistency, the same way as 05124614. In all 12 frames
across five sessions, byte 0 equals the 05FF4606 byte that byte 1 indexes
(1-based) and byte 2 equals the 05FF4606 byte that byte 3 indexes:

  1C011C01  28 @ 1, 28 @ 1   05FF4606 = 1C 1C 1C
  1D011C03  29 @ 1, 28 @ 3   05FF4606 = 1D 1D 1C
  1E011D03  30 @ 1, 29 @ 3   05FF4606 = 1E 1E 1D
  1E011E01  30 @ 1, 30 @ 1   05FF4606 = 1E 1E 1E

Four distinct payloads, values moving between sessions, indices moving too.
The indices never point into 05FF4607, which is what establishes 05FF4606 as
the cell sensors and 05FF4607 as the others.

It is also the SOURCE of <ECU Info>'s Cell Temperature Max/Min. The console's
values change only in the first report after this frame is polled, and to this
frame's values, in every session where they changed at all (1, 2 and 4). The
console holds a cached copy refreshed by this poll -- see the correction on
05FF4606 for the wrong reading that came from treating it as live.

The last two bytes vary between 0x0010/0x00FF and 0x0100/0x01FF and are not
decoded.

Note the sensor indices here are 1-based, unlike the 0-based cell indices in
05124614. That is not a typo: index 1 picks out the byte that carries the
matching value in 05FF4606 only under 1-based numbering.";
CM_ SG_ 2232567317 MinTempIndex "[confirmed] Byte 3, 1-based index into 05FF4606. Reads 1 when all three cell sensors agree
and 3 when they do not, and 05FF4606 byte 2 was in fact the minimum each time
it read 3.";
CM_ SG_ 2232567317 MinTemp "[confirmed] Byte 2. Equals 05FF4606's byte at MinTempIndex in 12/12 frames: 28, 29, 30.";
CM_ SG_ 2232567317 MaxTempIndex "[confirmed] Byte 1, 1-based index into 05FF4606. Always 1 so far, and 05FF4606 byte 0 was
in fact a maximum in all 12 frames. Confirmed jointly with MinTempIndex, which
does move and points correctly each time.";
CM_ SG_ 2232567317 MaxTemp "[confirmed] Byte 0. Equals 05FF4606's byte at MaxTempIndex in 12/12 frames: 28, 29, 30 across sessions.";
CM_ BO_ 2214532352 "[confirmed] Reply to 02191500. 0x000000C3 = group 1 of <ECU Info> <Hardware Version>, verbatim.";
CM_ SG_ 2214532352 HardwareVersion "[confirmed] Bytes 0-3 = 0x000000C3. Appears as the first group of the serial's hardware version.";
CM_ BO_ 2214532353 "[confirmed] Reply to 02191501. 0x0000004A = group 1 of <ECU Info> <Firmware Version>, verbatim.";
CM_ SG_ 2214532353 FirmwareVersion "[confirmed] Bytes 0-3 = 0x0000004A. Appears as the first group of the serial's firmware version.";
CM_ BO_ 2230924544 "[confirmed] Reply to 02213500. 0x000000EB = group 2 of <ECU Info> <Hardware Version>, verbatim.";
CM_ SG_ 2230924544 HardwareVersion "[confirmed] Bytes 0-3 = 0x000000EB. Appears as the second group of the serial's hardware version.";
CM_ BO_ 2230924545 "[confirmed] Reply to 02213501. 0x00000004 = group 2 of <ECU Info> <Firmware Version>, verbatim.";
CM_ SG_ 2230924545 FirmwareVersion "[confirmed] Bytes 0-3 = 0x00000004. Appears as the second group of the serial's firmware version.";
CM_ BO_ 2232567040 "[confirmed] Reply to 02294500. 0x0500 = group 3 of <ECU Info> <Hardware Version>, which
the report writes as 05000000 -- these two bytes zero-extended. AA=45 is the
BMS: 05124502 at the same address carries its model string.";
CM_ SG_ 2232567040 HardwareVersion "[confirmed] Bytes 0-1 = 0x0500, the leading half of the serial's third hardware group.";
CM_ BO_ 2232567041 "[confirmed] Reply to 02294501. 0x0103 = group 3 of <ECU Info> <Firmware Version>, written 01030000 in the report.";
CM_ SG_ 2232567041 FirmwareVersion "[confirmed] Bytes 0-1 = 0x0103, the leading half of the serial's third firmware group.";
CM_ BO_ 2232567042 "[confirmed] The battery pack's model string in ASCII: 5250313353333541 is \"RP13S35A\".
Reply to 02294502, at the BMS identity address.

No signals are defined -- DBC has no string type and splitting it into eight
one-byte integers would make it less readable, not more. The value is the
finding.

WHY IT IS WORTH HAVING. \"13S\" is 13 cells in series, which independently
corroborates the cell count that +RESP:GTBMI reports and that
05FF4602-05FF4605 supply. It also confirms AA=45 as the battery's identity
channel, which is the keystone of the AA scheme in nodes.md: 45 is identity
and 46 is live data for the same component, so 15/16 and 35/36 are read the
same way.";
CM_ BO_ 2232567043 "[hypothesis] Reply to 02294503, unchanged in every session: 00150C0900000C62.

Bytes 1-3 are 0x15 0x0C 0x09 = 21, 12, 9, which reads as a manufacture date of
9 December 2021, and bytes 6-7 are 0x0C62 = 3170, which would be a serial
number within that batch. Both are guesses from shape alone: nothing in the
corpus varies, and there is one pack.

What would test it: read this frame from a second pack. A different date and a
different last word, with the same layout, would settle it; anything else
would not.";
CM_ BO_ 2231317504 "[confirmed] A 10-second uptime tick. Bytes 0-1 and 4-7 are always zero; bytes 2-3 rise
monotonically and never repeat, so every frame of this message is unique.";
CM_ SG_ 2231317504 Uptime "[confirmed] CONFIRMED -- the rate. In the 4 September corpus the field's change between
consecutive frames equalled the elapsed wall-clock time divided by 10, exactly,
at all 76 steps, including across a 2520 s gap that advanced it by 252. The
7 September session reproduced this independently: 706 steps, every delta
exactly 1, against 7060 s elapsed. Wall-clock time is the ground truth, so the
scale needs no further test.

CONFIRMED -- that it is uptime, not an odometer. The field read 2878 when the
4 September session ended and 509 when the 7 September session began, so it
resets. A power-cycle test was recorded in signals.toml as the way to tell
uptime from an odometer, and this is that test passing.

CONFIRMED -- wider than 10 bits. discover.candidate_fields() reports only the
low 10 bits as active within one session, but the 7 September session ran the
field from 509 to 1215, straight past the 1023 where a 10-bit field would wrap,
monotonically and with every delta 1.

CONFIRMED -- that it keeps counting with the recorder switched off. The three
7 September sessions are one continuous run of this counter, to the exact
tick: it ends session 1 at 1215 and begins session 2 at 1389, and the wall
clock gap is 1740 s = 174 ticks; it ends session 2 at 1425 and begins session
3 at 1489, gap 640 s = 64 ticks. Both exact. So the count is tied to elapsed
time and not to anything the recorder does, and those three sessions are one
unbroken 10,070 s of bike uptime with no power cycle in between -- which is
what makes them comparable with each other.

A fourth gap reproduces it after the pack removals reset the count. The
reboot session ends at 124 and the max-speed session begins at 226, and the
gap between those two frames is 1020.0 s = 102 ticks. Exact again, and this
one matters more than the first three: the recorder was not merely switched
off across it, the bike was left alone for 17 minutes with nothing observing
it at all, and the counter still arrived at the value elapsed time predicts.

CONFIRMED -- that an IoT reboot does not reset it. Only pack power-on does.
The reboot session issued three REBOOT commands, all three acknowledged by
+ACK:GTRTO and all three corroborated by a +RESP:GTPNA / +RESP:GTPFA pair,
and across all of them this counter ran 48 -> 124 with every delta exactly 1
and no reset. So the reset condition established from the battery-removal
session is specific: the pack, not the IoT module, and not the ECU coming
back up. This is what separates the two readings of \"power-cycle the bike\".

RESOLVED -- which component sends it, as far as the address scheme goes. It is
AA=34, and 04FF3604 (the 30 ms message) and 02203606 (the headlight bit) are
AA=36 and AA=35's neighbours in the same component group. See nodes.md: AA
reads as <component><channel>, and channel 4 is a 10 s counter. This is the
only one of the three such counters that runs while the bus sleeps, so
whatever component 3 is, it stays powered through sleep. Three of the other
identifiers at that component are the fastest and the slowest messages on the
bus, which is what a controller looks like.

CORRECTION -- it is not powered permanently, only through sleep. That earlier
wording is disproved by the 7 September battery-removal session: with the pack
out, this identifier stops with everything else. Component 3 is supplied from
the pack.

UNKNOWN -- whether it is 16 or 32 bits. Bytes 0-1 are always zero, so they
could be the high half of a 32-bit value. Separating the two needs more than
7.6 days of continuous uptime, which is when a 16-bit field would wrap. The
longest continuous run recorded is 15,160 s.

RESOLVED -- what event starts the count: pack power-on. The 7 September
battery-removal session pulled the pack four times, and the counter behaved
identically every time: it read 2282 before the first removal, and after each
of the four restores its first frame arrived +10.009, +9.992, +10.010 and
+10.011 s later carrying 0. Four resets out of four, each exactly one tick
after power returned. This also settles the earlier drop from 2878 to 509
between 4 and 7 September: the pack had been off the bike.

That makes this counter volatile, which separates it from 02F82400. Over the
same four sessions 02F82400 ran 965 -> 969 -> 971 -> 980 -> 981 -> 987 -> 992
-> 994 without a single reset, including across the four pack removals. Two
counters, two components, one held in volatile memory and one not.";
CM_ BO_ 2197300224 "[confirmed] A second 10-second counter, at AA=24, and NOT the same quantity as
04FF3400. This one counts only the time the bus spends awake.

Proved by the sleep gaps. Between session 1 and session 2 the bike slept for
2390 s and this counter advanced by 2; between sessions 2 and 3 it slept 947 s
and it advanced by 1. Over the same two gaps 04FF3400 advanced by 174 and 64,
exactly the wall clock. Within a session the two run at the same rate, so the
difference is not the scale: this counter stops when the bus does.

It also skips correctly across the short sleep inside session 2. The bus was
down from 113.6 s to 127.0 s, and the counter advanced 1 tick over the 20 s of
wall clock that straddles it -- about 7 s of which the bus was awake.

Cumulative total when first recorded: 965 ticks, so this bike has spent about
2.7 hours awake since whatever last reset the field.

03FF1400 is the same quantity at another address. See nodes.md for the three
semantics side by side. 05FF4400 used to be listed with them and is not a
clock at all; see BmsSequence_4400.

It is also the non-volatile one. It ran 965 -> 969 -> 971 -> 980 -> 981 -> 987
-> 992 -> 994 across the four sessions without a single reset, and the last
step spans the four pack removals of the battery-removal session. 04FF3400
resets at every one of them.

CORRECTION -- \"non-volatile\" is wrong. It read 994 at the end of the
battery-removal session and 0 at the start of the unlock/lock session, running
0-4 there and 5-11 in the set-speed session after it. The only thing recorded
between 994 and 0 is the reboot session, in which the IoT module was rebooted
three times by remote command. So this counter survives four pack removals and
does not survive an IoT reboot. That is what a value held in RAM looks like
when the RAM belongs to the one component with its own backup battery: the
tracker kept running through every blackout (GTFRI reported 4.07 V on its
backup cell) and its memory was never lost until it was told to restart.

The plainest reading is that AA=24 is the IoT module's own channel, and by
extension AA=26 (the nonce and the MEULK challenge, which the IoT module is
the component that receives). See nodes.md, which had AA=24/26/27 down as a
component whose channels did not line up.

CORRECTION -- \"awake time\" is imprecise; it counts UNLOCKED time. In the two
recordings where the bus was woken without an UNLOCK (the reboot session's
three IoT reboots, and the 190 s after the last pack restore in the
battery-removal session) this identifier did not appear at all, while ~65
others did. It appears only after UNLOCK, and its first frame in the
battery-removal session is 2.9 s after that session's UNLOCK.

The reset was not observed directly -- no recording contains both 994 and 0
-- so it is a strong inference, not a measurement. What would confirm it: an
UNLOCK before and after a single REBOOT in one recording.";
CM_ SG_ 2197300224 AwakeTime "[confirmed] Bytes 0-1, LITTLE-endian, 10 s per count. C503 reads as 0x03C5 = 965, and the
five frames of session 1 run 965, 966, 967, 968, 969 at 10 s apart. Read
big-endian the sequence would be 0xC503, 0xC603, ... jumping by 256 a step,
which no clock does. The three sessions run 965-969, 971-980, 981-987
continuously.

Every one of the 22 steps recorded is exactly +1. Bytes 2-7 are always zero.

Note the endianness differs from 04FF3400, which is big-endian. Two counters,
two conventions, on the same bus.";
CM_ BO_ 2214532096 "[confirmed] Cumulative awake time again, at AA=14, big-endian and 32 bits wide. Same
quantity and same rate as 02F82400, different origin: it read 0 at the start
of the 7 September corpus and 16 at the end, so it had been reset shortly
before, where 02F82400 was already at 965.

Advanced by 1 over the 2402 s sleep between sessions 1 and 2 and by 1 over the
961 s sleep between 2 and 3, against 240 and 96 ticks of wall clock. So it too
counts awake time and not elapsed time.

RESOLVED -- its reset condition, which nodes.md listed as unknown: pack power.
It read 16 at the end of session 3, and 0 then 1 after the four pack removals
of the battery-removal session; then 2 in the reboot session, 3-6 and 7-13 in
the two sessions after that, with no reset across the three IoT REBOOTs. That
is the mirror image of 02F82400, which survived the pack removals and reset
across the reboots. Two awake-time counters, one in a pack-powered component
(AA=14, component 1) and one in the IoT module.

Like 02F82400 it did not run during the IoT-triggered wakes, except for a
single frame (value 2) 3 s into the first reboot wake. One frame is not enough
to say whether it ticks in that state.";
CM_ SG_ 2214532096 AwakeTime "[confirmed] Bytes 0-3 big-endian, 10 s per count. 0x0000000A = 10. Runs 0-3 in session 1,
4-11 in session 2, 12-16 in session 3, every step exactly +1, and skips the
short sleep inside session 2 exactly as 02F82400 does.";
CM_ BO_ 2248098816 "[probable] A counter the BMS increments once per frame of this message. NOT a clock.

CORRECTION. This was recorded as \"BmsAwakeTime_4400\", a fourth 10-second
counter that reset after a long sleep, and the whole reading was wrong. It
survived three sessions because this message is usually sent about every
10.5 s, so the count and the wall clock advanced together by coincidence.

The 7 September battery-removal session broke the coincidence. There the
transmit intervals are 3.1, 68.3, 4.2, 42.8, 4.1, 35.9, 4.1, 27.7, 2.7, 10.5
and 10.5 s, and the value steps by exactly +1 at every one of them. A 10 s
tick cannot advance by 1 in 2.7 s, and cannot advance by only 1 across 68.3 s.

What is true instead, over the whole corpus: the value equals the frame's
index within the session, 0, 1, 2, ..., in all 37 frames of all four
sessions, with no exception and no gap.

CORRECTION -- \"frame index within the session\" is also wrong, or at least the
\"within the session\" part is. The reboot session runs 12, 13, 14, 15, 16, 17,
continuing from the battery-removal session's 11 across a 430 s gap and
three IoT reboots. It steps by exactly +1 per frame everywhere, so \"counts
frames\" stands; what resets it does not. Observed: it read 0 on the first
frame after UNLOCK in sessions 1, 2, 3, 8 and 9, all of which followed a sleep
of at least 640 s; it did NOT reset at the UNLOCK in the battery-removal
session (8, with the BMS already awake from the pack restores), nor across a
495 s sleep inside the reboot session, nor across any pack removal or IoT
reboot. A BMS-side sleep timer somewhere between 495 and 640 s would fit all
of that, and it is the only candidate left for measuring the deep-sleep
threshold -- but that is one bracket from one pair of gaps, not a finding.

CONSEQUENCE -- the deep-sleep threshold experiment recorded here is void. It
was going to lock the bike, wait a measured interval, unlock, and read this
field as elapsed time. It is a frame index, so it would have measured nothing.
The 51 s / 947 s bracket that came from it should not be relied on.

It stays \"probable\" rather than \"confirmed\" because \"counts frames\" and
\"counts an event that happens once per frame\" cannot be told apart from the
recordings. What is confirmed is the negative: it does not measure time.";
CM_ SG_ 2248098816 Sequence "[probable] Bytes 0-3 big-endian. Steps by exactly +1 per frame in all 58 frames across
seven sessions: 0-4, 0-10, 0-8, 0-11, then 12-17 (continuing from the 11),
0-6 and 0-7. See the message comment for what is and is not known about the
reset.

It did not reset at any of the four pack removals in the battery-removal
session, while every counter on the bike itself did. That is expected and is
worth keeping: the BMS travels inside the pack, so pulling the pack off the
bike never interrupts its supply. It is independent support for AA=44/45/46
being inside the battery.";
CM_ BO_ 2197759490 "[probable] Eight bytes of high-entropy data, fresh every time, every 10 s while the bike
is awake. Every frame recorded is unique:

  1DF37DBD1F0BFC27   5B3BA3150375D83B   5D730D0D3E702E5F
  A243CE652C7E6F53   DAF3C66533E81ED7   3D13C50D00ED4D2B

No signals are defined and none should be: a value that is different every
time carries no field to fit. Writing it down is the finding.

WHY THIS LOOKS LIKE AUTHENTICATION rather than noise. It arrives 30 ms after
each tick of 02F82400, the awake-time counter, in every instance -- a counter
paired with an unpredictable value is the shape of a rolling code, and a
counter is exactly what stops one being replayed. The same address, AA=26,
carries the challenge that MEULK produces (02472602).

CORRECTION -- \"in every instance\" was true of the sessions then on record and
is false in general. In the 190 s after the last pack restore in the
battery-removal session this nonce was sent 28 times, and in the reboot
session 11 times, with 02F82400 absent from the bus on both occasions. The
pairing holds whenever the bike is unlocked; it is not a dependency. What the
two do still share is an owner: 02F82400 turns out to reset on an IoT reboot
(see AwakeTime_2400), so both AA=24 and AA=26 look like the IoT module's own
traffic, which is the natural sender of an authentication challenge.

Bytes 0-7 all vary, entropy 2.5 bits per byte over 7 frames, which is as high
as 7 samples can show. Nothing in it correlates with anything measured.

TREAT WITH CARE. If this is an immobiliser handshake then replaying or forging
it is the interesting part, and this project does not transmit. Never put a
transmitter on this identifier as a flag on the capture path.";
CM_ BO_ 2185700866 "[confirmed] A single frame of eight high-entropy bytes, sent once per MEULK command.

Twice recorded, twice different: C2D31EB512687FF3 on 7 September and
52539E5502CBE49B on 4 September. Same address family as the 10 s nonce
(AA=26), unique TT=47.

It opens a fixed five-second exchange that is byte-for-byte identical in both
corpora apart from the challenge itself:

  02472602  <8 random bytes>   x1
  08122602  0100000000000000   x4   first reply 0.07 s later
  02407600  0100000000000000   x5
  08F97603  0101000000000000   x6

The sequence runs with the bus otherwise ASLEEP -- in the 7 September session
it happened 27 s after LOCK -- so whatever it releases does not need the ECU
awake.

CONFIRMED -- this exchange releases the battery. The battery-removal session
issued MEULK four times and the pack came off the bike four times. Each time,
the exchange ran and then the ENTIRE BUS went silent, heartbeat included, at
+2.98, +3.00, +3.11 and +3.04 s after the +ACK:GTRTO. The serial console kept
running on its own backup cell throughout and reported main_power_v = 0.000 in
every blackout against 53.5 V outside them, so pack power really was gone and
not merely quiet.

There is no unexplained blackout in the session and no MEULK without one.

The 3.0 s is not operator reaction time: it varies by 0.07 s over four trials,
which no hand achieves, and it falls at the end of the CAN exchange rather than
at a fixed offset from the command. The disconnection follows the handshake.
What is NOT established is the mechanism -- whether the pack contactor opens
and the operator then lifts a dead pack out, or the latch releases and the
contacts break as the pack moves. Both fit. Telling them apart needs the pack
released and left in place.

Those four identifiers plus the five that survive a sleeping bus plus the four
light identifiers are exactly the 13 in the 4 September corpus, which accounts
for that recording completely.";
CM_ BO_ 2231318020 "[hypothesis] The fastest message on the bus at 30 ms, and the most valuable unknown. Not
decoded, but enough is now known to rule things out and to say what to record
next.

Layout, identical in all three 7 September sessions (1308, 2703 and 1881
frames):

  byte 0  always 0        byte 4  always 0
  byte 1  1 to 9          byte 5  200, or 0 for the first second after waking
  byte 2  always 0        byte 6  0 or 1, in brief bursts around a wake
  byte 3  2 to 4          byte 7  always 0

So bytes 0-1 and 2-3 are two 16-bit values, both far below 256, and bytes 4-5
hold the constant 200.

NOT A LAMP. Byte 1 has mean 4.47 and byte 3 mean 3.05, both fluctuating every
30 ms with no correlation between them (r = 0.07). That is two analogue inputs
idling at a small offset, sampled at 33 Hz. A lamp does not need 33 Hz and
does not need two noisy channels. Whatever the address AA=36 means, this is
not the headlight's own traffic.

WHAT IT IS PROBABLY. Two ADC channels reading near zero on a stationary bike,
with 200 as a fixed limit or scale. The torque sensor, the throttle and the
motor current are all in that shape and all read zero here. The bike has never
been ridden, so a channel that is zero when stationary cannot be told from a
channel that is broken or from an offset.

WHAT WOULD SETTLE IT, in order of cost:
  1. Ride it. Any motion at all separates speed and torque from everything
     that stays flat, and this message will move first because it is fastest.
  2. Turn the throttle and squeeze each brake on the bench with the bike
     unlocked. Those move one channel at a time without the bike moving.
  3. Watch byte 5. It sits at 0 for the first second after each wake and then
     goes to 200 and stays. If 200 is a limit, riding should not change it.

USE THIS MESSAGE AS THE WAKE DETECTOR. Its active runs bound the awake window
better than anything else on the bus: they begin 2.1-2.6 s after each UNLOCK
and end 0.3-0.8 s after each LOCK, over four unlocks and three locks. That is
how the lock latency asymmetry was shown to be the bus waking rather than a
latch -- see 13B76400.Unlocked.

UPDATE over ten unlocks and eight locks in seven sessions: runs begin 2.05 to
3.20 s after UNLOCK and end 0.26 to 0.81 s after LOCK. The one 3.20 s start is
the first unlock of the HubLock-disconnected session. Layout is identical in
all seven sessions (9,891 frames): byte 1 mean 4.46-4.53, byte 3 mean
3.04-3.07, r = 0.05-0.13.

It is specifically an UNLOCK detector, not a bus-activity detector. The bus can
be woken without an unlock -- an IoT REBOOT does it, and so does a pack
restore -- and this message does not appear in either case while ~65 others
do. See nodes.md, \"An IoT reboot wakes the bus\".

UPDATE, 9 September stationary-pedalling session: NOT speed, NOT cadence, NOT
torque. Through four loops of pedalling with 03FF1603 bytes 0-1 ramping to
~25 km/h and the motor drawing up to 0.86 A, both channels sat at their idle
2-9 exactly as on a stationary bike. What did happen: AnalogueA read exactly
0x0555 (1365) for 1.4 s and 0.8 s at the instant pedalling stopped in loops 1
and 2, with byte 6 = 1 throughout the run, and AnalogueB read 0x0555 for
1.9 s in the middle of loop 2. 1365 is one third of a 12-bit full scale and
never appears as any other value, so it is a sentinel, not a measurement.
Item 1 of the list above is done and did not settle it; item 2 -- throttle
and brakes -- is now the test. Three brake presses in this session showed no
byte or bit changing only around them, but the marks were typed after the
fact, so that is a weak negative.";
CM_ SG_ 2231318020 Constant200 "[hypothesis] Bytes 4-5. Holds 200 (0xC8) in all but the first second after a wake, where it
is 0, and in a 90 ms blip during a re-unlock. Named for what it is rather than
what it might mean. A limit, a scale or a commanded setpoint would all look
like this; only riding will tell them apart.";
CM_ SG_ 2231318020 AnalogueB "[hypothesis] Bytes 2-3. Stationary value 2 to 4, mean 3.05, uncorrelated with AnalogueA
(r = 0.07) -- which is the reason to believe they are two separate channels
rather than one 32-bit value.";
CM_ SG_ 2231318020 AnalogueA "[hypothesis] Bytes 0-1. Byte 0 has been zero in all 5892 frames recorded, so the width is a
guess; 16 bits is written because bytes 2-3 clearly pair the same way.
Stationary value 1 to 9, mean 4.47, resampling every 30 ms. Unnamed on purpose:
calling it Torque or Throttle would record a guess as a fact.";
CM_ BO_ 2214532611 "[probable] Component 1's 105 ms status frame. Two fields, not one.

CORRECTION -- this was recorded as one 32-bit big-endian value in bytes 0-3, a
\"voltage-like\" reading latched at power-up. That layout was an artefact of the
bench: bytes 0-1 had been zero in every frame ever recorded because the bike
had never moved. In the 9 September stationary-pedalling session
(2026-09-09T16-10-23) bytes 0-1 rose from 0 to 244, 256, 218 and 230 in the
four unlocked loops and returned to 0 within two seconds of the pedals
stopping, while bytes 2-3 kept holding a number near 0xD9xx. So bytes 0-1 are
a live value and bytes 2-3 are the field the old note described. The old
argument that 0x0000D11F \"is within 0.3 % of the pack voltage\" was about bytes
2-3 all along and is kept below, weakened.

The same trap as 02181606 byte 2 (max speed read as brightness): a field that
nobody has exercised looks exactly like a constant, or like padding.";
CM_ SG_ 2214532611 VoltageLike "[hypothesis] Bytes 2-3 big-endian (CORRECTION: previously bytes 0-3; see the message
comment). Everything recorded about the 32-bit value applies to this field
unchanged: seven distinct values across the 7 September sessions, all within
0.3 % of the pack voltage at the time, quantised in ~16.6 mV steps; re-latched
at component 1's power-up (pack restores), not at wake.

WEAKENED on 9 September. In the pedalling session it took 14 distinct values
(0xD78A to 0xD94A, 55178-55626) while the BMS reported 52.8 V, i.e. 2.4-2.8 V
ABOVE the pack rather than 0.1 V below it, and it moved during pedalling. The
\"coarse supply reading\" story does not survive that offset unchanged. Kept as
mV so the comparison stays easy to run; do not rely on it.";
CM_ SG_ 2214532611 Speed "[probable] Bytes 0-1 big-endian. Zero whenever the bike is not being pedalled: every
frame of every session before 9 September, and every non-pedalling second of
the pedalling session. Non-zero only while the pedals turned.

Read as 0.1 km/h because of where it tops out. Peaks in the four loops were
244, 256, 218 and 230 -- 21.8 to 25.6 km/h, straddling the 25 km/h limit the
bike is configured to (03FF1600 / 02181606 byte 2), which is where a pedelec
controller stops assisting. The value ramps up over 5-8 s and decays over
about 2 s, and does not oscillate stroke by stroke as a torque reading would
at this sample rate.

ASSUMPTION: the rear wheel was off the ground (or on a stand) and spinning
while the rider pedalled; a stationary bike produces no speed otherwise. This
was not confirmed at the time of recording. Motor current (05FF4610) rose to
0.45-0.86 A only in loop 2, so the motor assisted in one loop of four.

WHAT WOULD CONFIRM IT: ride at a steady GPS speed and compare with GTFRI's
speed field, which stayed 0.0 throughout this stationary session. WHAT WOULD
DISPROVE IT: a ride where this reads 0, or where it tracks effort rather than
GPS speed. If the wheel turns out not to have been spinning, this is not
speed; cadence x 10 or a filtered torque would be the next candidates, though
244 rpm is not a cadence a rider produces.";
CM_ BO_ 2214531072 "[probable] A heartbeat. Every 105 ms, payload 0840112200000001. It runs while the bus
sleeps, so it is one of the five identifiers a locked bike still sends. Node
field 10->00 appears nowhere else.

CORRECTION -- it is not invariant. This was recorded as \"never varies\",
byte-identical across 80,872 frames of four sessions. That was true of every
recording made up to then and it was still the wrong conclusion, because not
one of those recordings contained a cold boot. The battery-removal session
supplied four, and in each of them byte 0 is 0x00 for the first two seconds
after power returns and 0x08 for ever after. See SystemReady below.

SECOND CORRECTION -- the payload is per bike. The 9 September sessions come
from a different bike (see \"Two bikes in the corpus\" in nodes.md) and its
heartbeat is 0000112200000001 in all 7,241 frames: byte 0 is 0x00 throughout,
unlocked and pedalling included, and byte 1 is 0x00 where bike 1 has 0x40. So
bytes 0 and 1 are not boot state, or not only boot state; they differ between
two bikes that share hardware version, BMS model and bus layout, and differ in
firmware (0x4A/0x0103 against 0x51/0x0104). Bytes 2-7 (11 22 00 00 00 01) have
never varied, across 101,080 frames and thirteen sessions.

It stays \"probable\" rather than confirmed because nothing has tied it to a
component or an action. Calling it a heartbeat is an inference from its shape.";
CM_ SG_ 2214531072 SystemReady "[hypothesis] Bit 0x08 of byte 0. On the 7 September bike: clear for the first seconds after
the pack is connected, then set, and it never clears again while power is
held.

CORRECTION, downgraded from \"probable\" to \"hypothesis\". The 9 September bike
never sets this bit: 7,241 frames across three sessions, all 0x00 in byte 0,
while unlocked, pedalling and reporting ECU speed up to 24.3 km/h. A bike
that is plainly running with the bit clear is the disproof the paragraph at
the end asked for, in a form it did not anticipate. The bit still marks the
first two seconds after a cold boot on bike 1, so the boot timing below
stands as an observation of that bike; what the bit means is open. It is not
\"system ready\" in any sense that holds across the two bikes. The name is kept
so existing filters still work; treat it as a label, not a reading.

Four pack removals in the 7 September battery-removal session, four identical
boots. The heartbeat itself restarts +0.10 to +0.12 s after power returns,
already carrying 0x00; the bit sets at +2.01, +2.10, +2.22 and +1.70 s. Every
one of the 711 frames recorded before the first removal has it set, as does
every frame of the three earlier sessions and the 4 September corpus.

Reading it as \"initialised\" is an inference from the timing, not a
measurement, which is why this is \"probable\". Two facts support it: the delay
is close to the 2.1-2.6 s that 04FF3604 takes to start after an UNLOCK, and
04FF3400 issues its first tick 10 s after the same instant.

WHAT WOULD DISPROVE IT: a recording where the bit clears without a power
interruption -- during a ride, a fault, or a lock/unlock. That would make it a
status bit rather than a boot flag. (Written when the corpus contained only
four boots and one bike; the second bike then did something this did not
foresee, see the correction above.) WHAT WOULD SETTLE IT NOW: a cold boot of
bike 2, to see whether the bit ever sets there; and any state on bike 1 that
clears it without a power cut.";
CM_ BO_ 2683875368 "[probable] One all-zero frame per lock-state transition. Listed in nodes.md as a constant
until the 9 September unlock/lock session; the payload IS constant, the timing
is not.

Across all eleven sessions it appears exactly once per UNLOCK and once per
LOCK: 2.3-3.4 s after the +ACK:GTRTO UNLOCK and 0.4-0.9 s after the
+ACK:GTRTO LOCK, always within about 0.1 s of the first 13B76400 frame of the
transition -- just before it on UNLOCK, just after it on LOCK. About 30
occurrences, none without a transition nearby. It fired in the three sessions
recorded with the HubLock removed, so the HubLock does not send it. It also
fired about 24 s after each IoT REBOOT and around each MEULK in the
battery-removal session, which may be transitions of the same state or may
not; that is why this is \"probable\" and not \"confirmed\".

No signals: every byte is 0 in every frame. Use the frame's presence as a
transition marker.

WHAT WOULD DISPROVE IT: a LOCK or UNLOCK transition with no 1FF8B028 within a
few seconds, or a 1FF8B028 with no transition. The REBOOT and MEULK
occurrences are the ones to look at: if the lock state can be shown not to
change there, this is not a lock-transition marker but something broader,
such as \"component 3 changed state\".";
CM_ BO_ 2214532610 "[hypothesis] Component 1, 1 Hz while awake. Two counters that only advance while
03FF1603.Speed is non-zero, seen in the 9 September stationary-pedalling
session. Neither has been checked against a measured distance, hence
\"hypothesis\" for both. Payload example while pedalling: 07 5A 86 00 00 12 13 24.";
CM_ SG_ 2214532610 TripDistance "[hypothesis] Bytes 4-5 big-endian. 0 at each UNLOCK, counts up only while Speed is
non-zero, holds when it returns to 0, and resets to 0 at the next UNLOCK.
Reached 81 in loop 1 and 102 in loop 2. Integrating the Speed signal over
those loops gives roughly 90 m and 110 m, so metres fit within the accuracy of
the integration. WHAT WOULD CONFIRM IT: ride a measured 100 m from an unlock
and read this. WHAT WOULD DISPROVE IT: any ride where it disagrees with the
distance by more than the speed integration does.";
CM_ SG_ 2214532610 Odometer "[confirmed] Bytes 0-2 big-endian in 10 m units, matched to the console's measured total
mileage on two bikes. 9 September bike: 0x075A85 = 481925 -> 4819.25 km at the
start of the pedalling session and 0x075AA2 -> 4819.54 km at its end, while
+RESP:GTFRI <ECU Total Mileage> on the same clock read 4819.3, 4819.4, 4819.5.
7 September bike: 0x000005 -> 0.05 km against a reported 0.1 km, the same
value at GTFRI's 0.1 km resolution. Byte 2 stepped 133 -> 141 -> 151 across
loops 1 and 2 (+8, +10) while TripDistance reached 81 and 102: one step per
ten metres of trip. It does not reset at UNLOCK.

CORRECTION: first recorded as bytes 1-2 with byte 1 a width guess, which gave
231.7 km. Byte 0 (0x07) is the high byte; without it the value disagreed with
GTFRI by a factor of twenty. WHAT WOULD DISPROVE IT: a ride where it advances
by other than TripDistance / 10, or a pack removal resetting it (an odometer
must not).";
CM_ BO_ 2214532612 "[hypothesis] Component 1, 1 Hz while awake. Two bytes move only while 03FF1603.Speed is
non-zero (9 September stationary-pedalling session); neither is decoded.
Payload example while pedalling: 00 81 00 05 00 00 00 00.

  byte 1  rises with Speed to 172-225 and then HOLDS its last value after the
          pedals stop (182 after loop 1, 193 after loop 2) until the LOCK.
          A held peak or a slowly filtered speed; not the live speed, which
          drops to 0.
  byte 3  counts 0 -> 16 in loop 1 and 0 -> 19 in loop 2, one step every
          second or so while pedalling, then holds. Seconds of assistance, or
          a coarser distance, would both look like this.

Recorded so that the next ride has something to check against. No signals
declared: naming either byte would record a guess as a fact.";
BA_DEF_ BO_  "GenMsgCycleTime" INT 0 65535;
BA_DEF_DEF_  "GenMsgCycleTime" 0;
BA_ "GenMsgCycleTime" BO_ 2214532608 1000;
BA_ "GenMsgCycleTime" BO_ 2248099330 1044;
BA_ "GenMsgCycleTime" BO_ 2248099331 1044;
BA_ "GenMsgCycleTime" BO_ 2248099332 1044;
BA_ "GenMsgCycleTime" BO_ 2248099333 1044;
BA_ "GenMsgCycleTime" BO_ 2248099334 1044;
BA_ "GenMsgCycleTime" BO_ 2248099335 1044;
BA_ "GenMsgCycleTime" BO_ 2248099344 273;
BA_ "GenMsgCycleTime" BO_ 2248099337 1044;
BA_ "GenMsgCycleTime" BO_ 2232567305 300000;
BA_ "GenMsgCycleTime" BO_ 2248099328 5223;
BA_ "GenMsgCycleTime" BO_ 2231317504 10000;
BA_ "GenMsgCycleTime" BO_ 2197300224 10000;
BA_ "GenMsgCycleTime" BO_ 2214532096 10000;
BA_ "GenMsgCycleTime" BO_ 2197759490 10000;
BA_ "GenMsgCycleTime" BO_ 2231318020 30;
BA_ "GenMsgCycleTime" BO_ 2214532611 105;
BA_ "GenMsgCycleTime" BO_ 2214531072 105;
BA_ "GenMsgCycleTime" BO_ 2214532610 1000;
BA_ "GenMsgCycleTime" BO_ 2214532612 1000;
